# ATtiny88 register map
Vendor: Atmel; File version: 1.0
CPU: other r0p0, little endian, no MPU, no FPU, 4 interrupt priority bits
Registers are 8-bit, read-write, reset 0x0 unless marked. A register's access mark holds for its fields unless they carry their own. Offsets are from the block's base; [hi:lo] are bit positions; {n}, {i} and the like mark numbered series.

## PORTC — I/O Port
Base 0x00800026
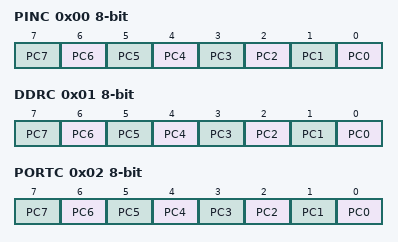
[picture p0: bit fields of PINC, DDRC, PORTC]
0x00 PINC — Port C Input Pins (read-only for debugger)
  [n] PC{n} (n=0..7) — Pin C{n}
0x01 DDRC — Port C Data Direction Register
  [n] PC{n} (n=0..7) — Pin C{n}
0x02 PORTC — Port C Data Register
  [n] PC{n} (n=0..7) — Pin C{n}

## PORTD — I/O Port
Base 0x00800029
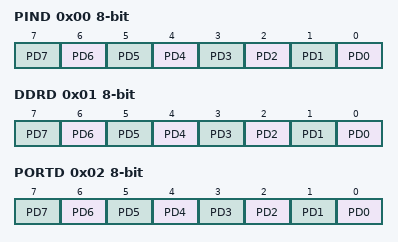
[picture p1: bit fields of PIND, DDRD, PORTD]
0x00 PIND — Port D Input Pins (read-only for debugger)
  [n] PD{n} (n=0..7) — Pin D{n}
0x01 DDRD — Port D Data Direction Register
  [n] PD{n} (n=0..7) — Pin D{n}
0x02 PORTD — Port D Data Register
  [n] PD{n} (n=0..7) — Pin D{n}

## SPI — Serial Peripheral Interface
Base 0x0080004C
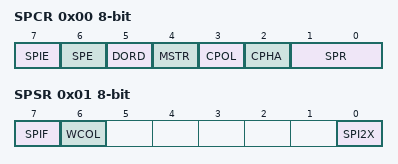
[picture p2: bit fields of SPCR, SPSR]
0x00 SPCR — SPI Control Register
  [7] SPIE — SPI Interrupt Enable
  [6] SPE — SPI Enable
  [5] DORD — Data Order
  [4] MSTR — Master/Slave Select
  [3] CPOL — Clock polarity
  [2] CPHA — Clock Phase
  [1:0] SPR — SPI Clock Rate Selects
    0=FOSC_4; 1=FOSC_16; 3=FOSC_128
0x01 SPSR — SPI Status Register (read-only for debugger)
  [7] SPIF — SPI Interrupt Flag
  [6] WCOL — Write Collision Flag
  [0] SPI2X — Double SPI Speed Bit
0x02 SPDR — SPI Data Register (write-only for debugger)

## TC0 — Timer/Counter, 8-bit
Base 0x00800035
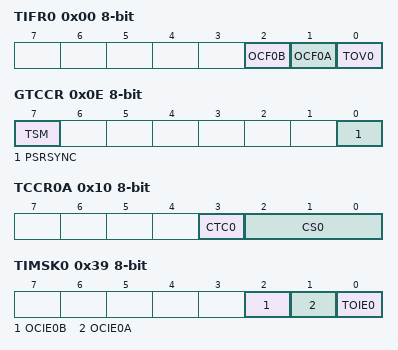
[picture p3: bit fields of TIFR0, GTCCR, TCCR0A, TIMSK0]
0x00 TIFR0 — Timer/Counter0 Interrupt Flag register (read-only for debugger)
  [2] OCF0B — Timer/Counter0 Output Compare Flag 0B
  [1] OCF0A — Timer/Counter0 Output Compare Flag 0A
  [0] TOV0 — Timer/Counter0 Overflow Flag
0x0E GTCCR — General Timer/Counter Control Register
  [7] TSM — Timer/Counter Synchronization Mode
  [0] PSRSYNC — Prescaler Reset Timer/Counter1 and Timer/Counter0
0x10 TCCR0A — Timer/Counter Control Register A
  [3] CTC0 — Clear Timer on Compare Match
  [2:0] CS0 — Clock Select
    0=NO_CLOCK_SOURCE_STOPPED; 1=RUNNING_NO_PRESCALING; 2=RUNNING_CLK_8; 3=RUNNING_CLK_64; 4=RUNNING_CLK_256; 5=RUNNING_CLK_1024; 6=RUNNING_EXTCLK_TN_FALLING_EDGE; 7=RUNNING_EXTCLK_TN_RISING_EDGE
0x11 TCNT0 — Timer/Counter0
0x12 OCR0A — Timer/Counter0 Output Compare Register
0x13 OCR0B — Timer/Counter0 Output Compare Register
0x39 TIMSK0 — Timer/Counter0 Interrupt Mask Register
  [2] OCIE0B — Timer/Counter0 Output Compare Match B Interrupt Enable
  [1] OCIE0A — Timer/Counter0 Output Compare Match A Interrupt Enable
  [0] TOIE0 — Timer/Counter0 Overflow Interrupt Enable

## TC1 — Timer/Counter, 16-bit
Base 0x00800036
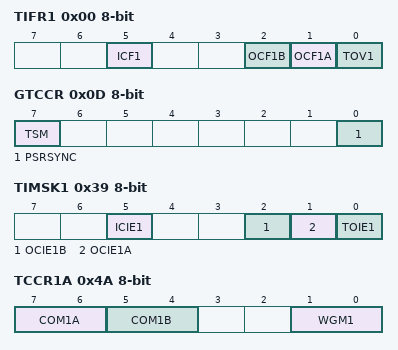
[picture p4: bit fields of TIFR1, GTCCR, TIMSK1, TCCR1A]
0x00 TIFR1 — Timer/Counter Interrupt Flag register (read-only for debugger)
  [5] ICF1 — Input Capture Flag 1
  [2] OCF1B — Output Compare Flag 1B
  [1] OCF1A — Output Compare Flag 1A
  [0] TOV1 — Timer/Counter1 Overflow Flag
0x0D GTCCR — General Timer/Counter Control Register
  [7] TSM — Timer/Counter Synchronization Mode
  [0] PSRSYNC — Prescaler Reset Timer/Counter1 and Timer/Counter0
0x39 TIMSK1 — Timer/Counter Interrupt Mask Register
  [5] ICIE1 — Timer/Counter1 Input Capture Interrupt Enable
  [2] OCIE1B — Timer/Counter1 Output CompareB Match Interrupt Enable
  [1] OCIE1A — Timer/Counter1 Output CompareA Match Interrupt Enable
  [0] TOIE1 — Timer/Counter1 Overflow Interrupt Enable
0x4A TCCR1A — Timer/Counter1 Control Register A
  [7:6] COM1A — Compare Output Mode 1A, bits
  [5:4] COM1B — Compare Output Mode 1B, bits
  [1:0] WGM1 — Waveform Generation Mode
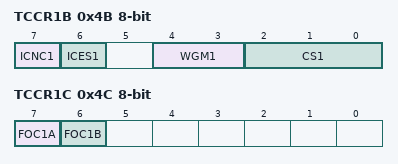
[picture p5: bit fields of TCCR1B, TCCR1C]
0x4B TCCR1B — Timer/Counter1 Control Register B
  [7] ICNC1 — Input Capture 1 Noise Canceler
  [6] ICES1 — Input Capture 1 Edge Select
  [4:3] WGM1 — Waveform Generation Mode
  [2:0] CS1 — Prescaler source of Timer/Counter 1
    0=NO_CLOCK_SOURCE_STOPPED; 1=RUNNING_NO_PRESCALING; 2=RUNNING_CLK_8; 3=RUNNING_CLK_64; 4=RUNNING_CLK_256; 5=RUNNING_CLK_1024; 6=RUNNING_EXTCLK_TN_FALLING_EDGE; 7=RUNNING_EXTCLK_TN_RISING_EDGE
0x4C TCCR1C — Timer/Counter1 Control Register C (write-only for debugger)
  [7] FOC1A, [6] FOC1B
0x4E TCNT1 16-bit (reset mask 0xFF) — Timer/Counter1 Bytes
0x50 ICR1 16-bit (reset mask 0xFF) — Timer/Counter1 Input Capture Register Bytes
0x52 OCR1A 16-bit (reset mask 0xFF) — Timer/Counter1 Output Compare Register Bytes
0x54 OCR1B 16-bit (reset mask 0xFF) — Timer/Counter1 Output Compare Register Bytes

## TWI — Two Wire Serial Interface
Base 0x008000B8
0x00 TWBR — TWI Bit Rate register
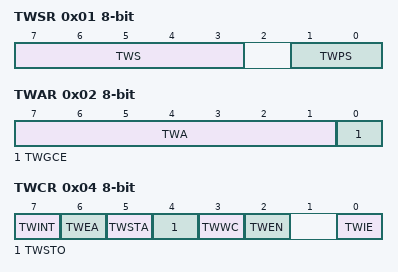
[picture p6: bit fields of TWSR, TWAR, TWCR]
0x01 TWSR — TWI Status Register
  [7:3] TWS — TWI Status
  [1:0] TWPS — TWI Prescaler
    0=1; 1=4; 2=16; 3=64
0x02 TWAR — TWI (Slave) Address register
  [7:1] TWA — TWI (Slave) Address register Bits
  [0] TWGCE — TWI General Call Recognition Enable Bit
0x03 TWDR — TWI Data register
0x04 TWCR — TWI Control Register
  [7] TWINT — TWI Interrupt Flag
  [6] TWEA — TWI Enable Acknowledge Bit
  [5] TWSTA — TWI Start Condition Bit
  [4] TWSTO — TWI Stop Condition Bit
  [3] TWWC — TWI Write Collision Flag
  [2] TWEN — TWI Enable Bit
  [0] TWIE — TWI Interrupt Enable
0x05 TWAMR — TWI (Slave) Address Mask Register
  [7:1] TWAM
0x06 TWHSR
  [0] TWHS

## WDT — Watchdog Timer
Base 0x00800060
0x00 WDTCSR — Watchdog Timer Control Register (read-only for debugger)
  [7] WDIF — Watchdog Timeout Interrupt Flag
  [6] WDIE — Watchdog Timeout Interrupt Enable
  [4] WDCE — Watchdog Change Enable
  [3] WDE — Watch Dog Enable
  [5:0] WDP — Watchdog Timer Prescaler Bits
    0=OSCILLATOR_CYCLES_2K; 1=OSCILLATOR_CYCLES_4K; 2=OSCILLATOR_CYCLES_8K; 3=OSCILLATOR_CYCLES_16K; 4=OSCILLATOR_CYCLES_32K; 5=OSCILLATOR_CYCLES_64K; 6=OSCILLATOR_CYCLES_128K; 7=OSCILLATOR_CYCLES_256K
